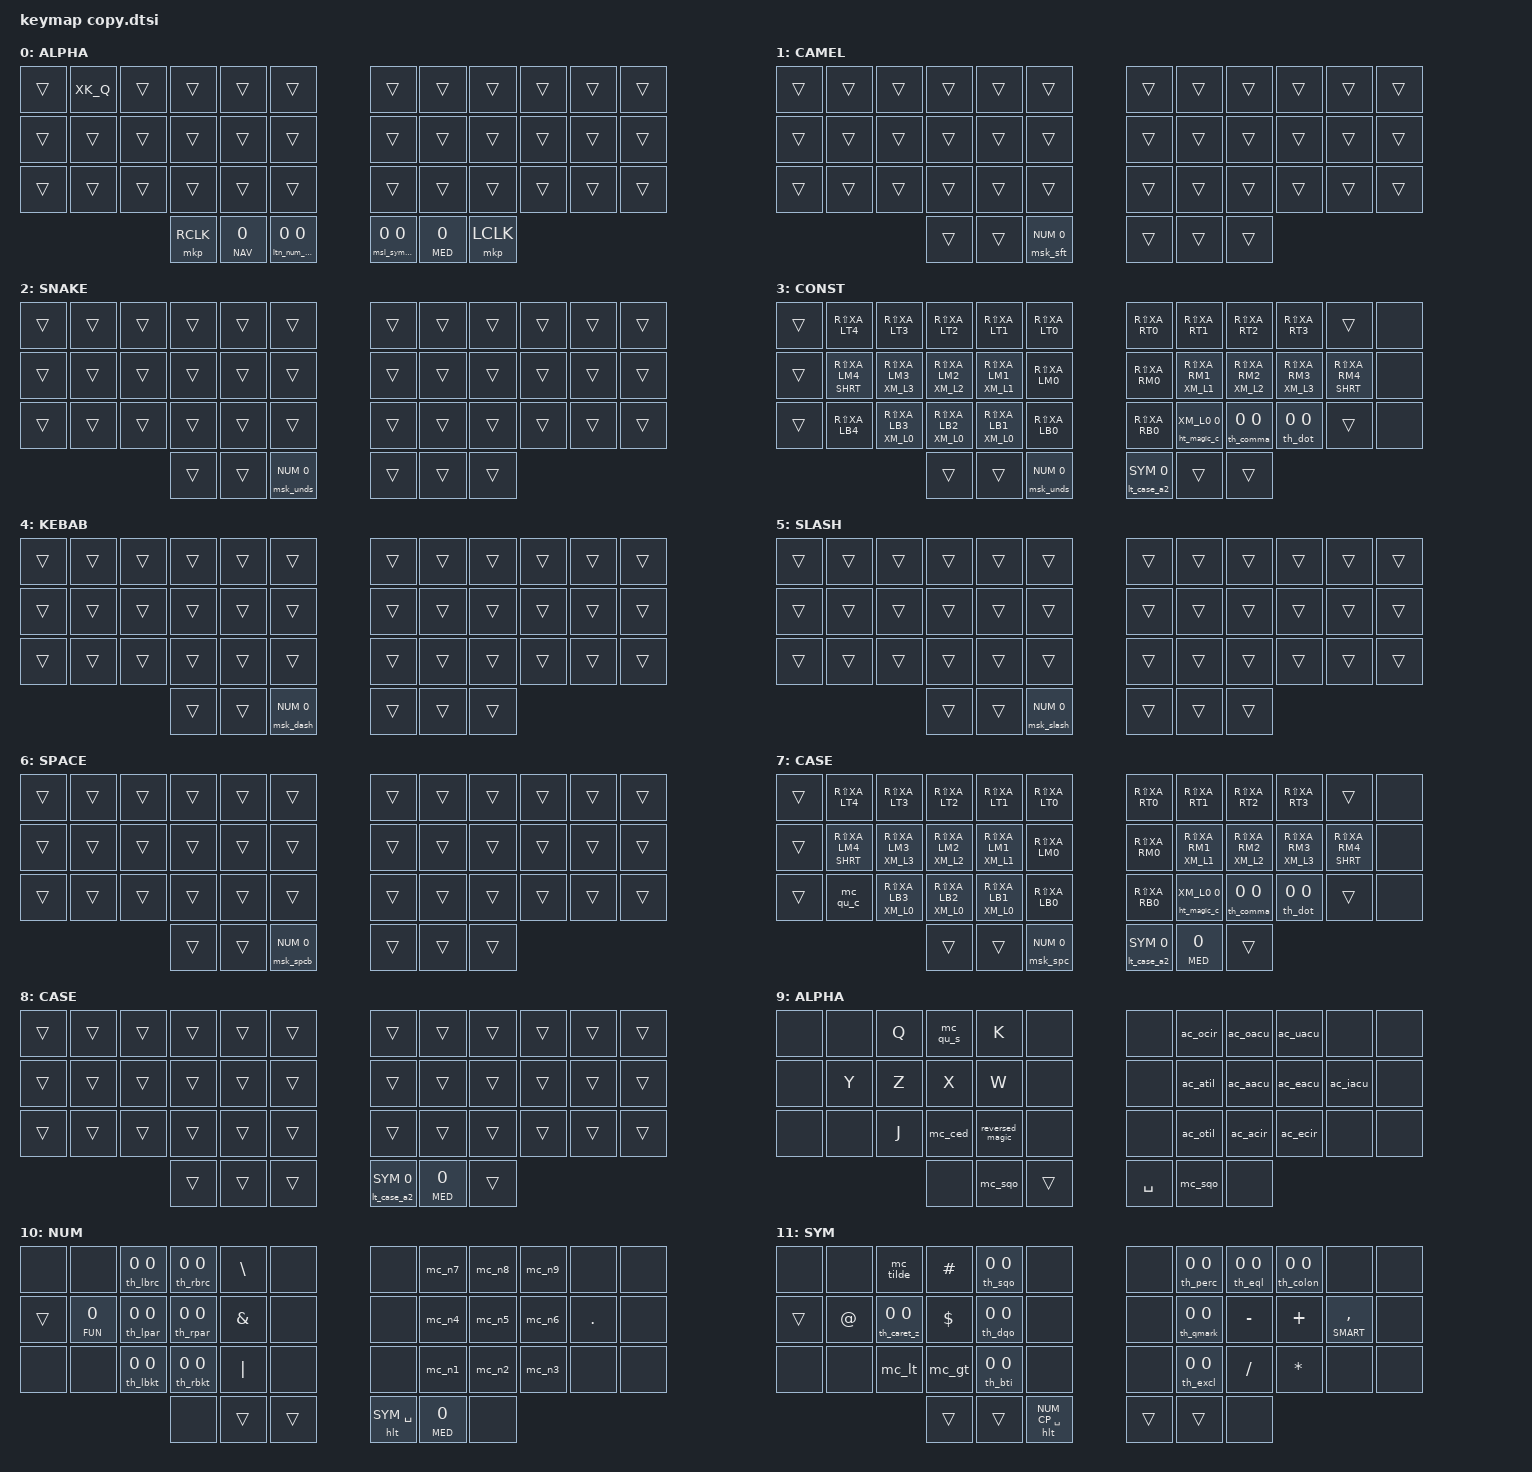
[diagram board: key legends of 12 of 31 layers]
/*
*
* Copyright (c) 2025 Ryan Luckie
* SPDX-License-Identifier: MIT
*
*/
/ {
      keymap {
          compatible = "zmk,keymap";
          default {
               display-name = "ALPHA";
               bindings = <
//╭────────────────────┬────────────────────┬────────────────────┬────────────────────┬────────────────────┬────────────────────┬────────────────────┬────────────────────┬────────────────────┬────────────────────┬────────────────────┬────────────────────╮
   // &trans               &kp XK_Q             &kp XK_W             &hrlm LHYP XK_E       &kp XK_R             &kp XK_T             &kp XK_Y            &kp XK_U             &hrrm RHYP XK_I      &kp XK_O             &kp XK_P             &trans
   &trans               &kp XK_Q               &trans               &trans               &trans               &trans               &trans               &trans               &trans               &trans               &trans               &trans
//├────────────────────┼────────────────────┼────────────────────┼────────────────────┼────────────────────┼────────────────────┼────────────────────┼────────────────────┼────────────────────┼────────────────────┼────────────────────┼────────────────────┤
   // &trans               &lt SHRT XK_A        &hrlm LCTRL XK_S     &hrlm LALT XK_D      &hrls LSHFT XK_F     &kp XK_G             &kp XK_H             &hrrs RSHFT XK_J     &hrrm RALT XK_K      &hrrm RCTL XK_L      &lt SHRT XK_SEMI     &trans
   &trans               &trans               &trans               &trans               &trans               &trans               &trans               &trans               &trans               &trans               &trans               &trans
//├────────────────────┼────────────────────┼────────────────────┼────────────────────┼────────────────────┼────────────────────┼────────────────────┼────────────────────┼────────────────────┼────────────────────┼────────────────────┼────────────────────┤
   &trans               &trans               &trans               &trans               &trans               &trans               &trans               &trans               &trans               &trans               &trans               &trans
//╰────────────────────┴────────────────────┴────────────────────┼────────────────────┼────────────────────┼────────────────────┼────────────────────┼────────────────────┼────────────────────┼────────────────────┴────────────────────┴────────────────────╯
                                                                  &mkp RCLK            &ht_repeat NAV 0     &ltn_num_spc 0 0     &msl_sym_a2 0 0      &ht_shift MED 0      &mkp LCLK
//                                                               ╰────────────────────┴────────────────────┴────────────────────┴────────────────────┴────────────────────┴────────────────────╯
                        >;
                };
          camel_case {
               display-name = "CAMEL";
               bindings = <
//╭────────────────────┬────────────────────┬────────────────────┬────────────────────┬────────────────────┬────────────────────┬────────────────────┬────────────────────┬────────────────────┬────────────────────┬────────────────────┬────────────────────╮
   &trans               &trans               &trans               &trans               &trans               &trans               &trans               &trans               &trans               &trans               &trans               &trans
//├────────────────────┼────────────────────┼────────────────────┼────────────────────┼────────────────────┼────────────────────┼────────────────────┼────────────────────┼────────────────────┼────────────────────┼────────────────────┼────────────────────┤
   &trans               &trans               &trans               &trans               &trans               &trans               &trans               &trans               &trans               &trans               &trans               &trans
//├────────────────────┼────────────────────┼────────────────────┼────────────────────┼────────────────────┼────────────────────┼────────────────────┼────────────────────┼────────────────────┼────────────────────┼────────────────────┼────────────────────┤
   &trans               &trans               &trans               &trans               &trans               &trans               &trans               &trans               &trans               &trans               &trans               &trans
//╰────────────────────┴────────────────────┴────────────────────┼────────────────────┼────────────────────┼────────────────────┼────────────────────┼────────────────────┼────────────────────┼────────────────────┴────────────────────┴────────────────────╯
                                                                  &trans               &trans               &msk_sft NUM 0       &trans               &trans               &trans
//                                                               ╰────────────────────┴────────────────────┴────────────────────┴────────────────────┴────────────────────┴────────────────────╯
>;
          };
          snake_case {
               display-name = "SNAKE";
               bindings = <
//╭────────────────────┬────────────────────┬────────────────────┬────────────────────┬────────────────────┬────────────────────┬────────────────────┬────────────────────┬────────────────────┬────────────────────┬────────────────────┬────────────────────╮
   &trans               &trans               &trans               &trans               &trans               &trans               &trans               &trans               &trans               &trans               &trans               &trans
//├────────────────────┼────────────────────┼────────────────────┼────────────────────┼────────────────────┼────────────────────┼────────────────────┼────────────────────┼────────────────────┼────────────────────┼────────────────────┼────────────────────┤
   &trans               &trans               &trans               &trans               &trans               &trans               &trans               &trans               &trans               &trans               &trans               &trans
//├────────────────────┼────────────────────┼────────────────────┼────────────────────┼────────────────────┼────────────────────┼────────────────────┼────────────────────┼────────────────────┼────────────────────┼────────────────────┼────────────────────┤
   &trans               &trans               &trans               &trans               &trans               &trans               &trans               &trans               &trans               &trans               &trans               &trans
//╰────────────────────┴────────────────────┴────────────────────┼────────────────────┼────────────────────┼────────────────────┼────────────────────┼────────────────────┼────────────────────┼────────────────────┴────────────────────┴────────────────────╯
                                                                  &trans               &trans               &msk_unds NUM 0      &trans               &trans               &trans
//                                                               ╰────────────────────┴────────────────────┴────────────────────┴────────────────────┴────────────────────┴────────────────────╯
>;
          };
          constant {
               display-name = "CONST";
               bindings = <
//╭────────────────────┬────────────────────┬────────────────────┬────────────────────┬────────────────────┬────────────────────┬────────────────────┬────────────────────┬────────────────────┬────────────────────┬────────────────────┬────────────────────╮
   &trans               &kp RS(XA_LT4)   &kp RS(XA_LT3)       &kp RS(XA_LT2)   &kp RS(XA_LT1)       &kp RS(XA_LT0)   &kp RS(XA_RT0)       &kp RS(XA_RT1)   &kp RS(XA_RT2)       &kp RS(XA_RT3)         &trans               &none
//├────────────────────┼────────────────────┼────────────────────┼────────────────────┼────────────────────┼────────────────────┼────────────────────┼────────────────────┼────────────────────┼────────────────────┼────────────────────┼────────────────────┤
   &trans               &lt SHRT RS(XA_LM4)    &mt XM_L3 RS(XA_LM3)   &mt XM_L2 RS(XA_LM2)   &mt XM_L1 RS(XA_LM1)   &kp RS(XA_LM0)       &kp RS(XA_RM0)   &mt XM_L1 RS(XA_RM1)   &mt XM_L2 RS(XA_RM2)   &mt XM_L3 RS(XA_RM3)   &lt SHRT RS(XA_RM4)  &none
//├────────────────────┼────────────────────┼────────────────────┼────────────────────┼────────────────────┼────────────────────┼────────────────────┼────────────────────┼────────────────────┼────────────────────┼────────────────────┼────────────────────┤
   &trans               &kp RS(XA_LB4)   &mt XM_L0 RS(XA_LB3)   &mt XM_L0 RS(XA_LB2)   &mt XM_L0 RS(XA_LB1)   &kp RS(XA_LB0)       &kp RS(XA_RB0)   &ht_magic_c XM_L0 0    &th_comma 0 0        &th_dot 0 0            &trans               &none
//╰────────────────────┴────────────────────┴────────────────────┼────────────────────┼────────────────────┼────────────────────┼────────────────────┼────────────────────┼────────────────────┼────────────────────┴────────────────────┴────────────────────╯
                                                                  &trans               &trans               &msk_unds NUM 0      &lt_case_a2 SYM 0    &trans               &trans
//                                                               ╰────────────────────┴────────────────────┴────────────────────┴────────────────────┴────────────────────┴────────────────────╯
>;
          };
          kebab_case {
               display-name = "KEBAB";
               bindings = <
//╭────────────────────┬────────────────────┬────────────────────┬────────────────────┬────────────────────┬────────────────────┬────────────────────┬────────────────────┬────────────────────┬────────────────────┬────────────────────┬────────────────────╮
   &trans               &trans               &trans               &trans               &trans               &trans               &trans               &trans               &trans               &trans               &trans               &trans
//├────────────────────┼────────────────────┼────────────────────┼────────────────────┼────────────────────┼────────────────────┼────────────────────┼────────────────────┼────────────────────┼────────────────────┼────────────────────┼────────────────────┤
   &trans               &trans               &trans               &trans               &trans               &trans               &trans               &trans               &trans               &trans               &trans               &trans
//├────────────────────┼────────────────────┼────────────────────┼────────────────────┼────────────────────┼────────────────────┼────────────────────┼────────────────────┼────────────────────┼────────────────────┼────────────────────┼────────────────────┤
   &trans               &trans               &trans               &trans               &trans               &trans               &trans               &trans               &trans               &trans               &trans               &trans
//╰────────────────────┴────────────────────┴────────────────────┼────────────────────┼────────────────────┼────────────────────┼────────────────────┼────────────────────┼────────────────────┼────────────────────┴────────────────────┴────────────────────╯
                                                                  &trans               &trans               &msk_dash NUM 0      &trans               &trans               &trans
//                                                               ╰────────────────────┴────────────────────┴────────────────────┴────────────────────┴────────────────────┴────────────────────╯
>;
          };
          slash_case {
               display-name = "SLASH";
               bindings = <
//╭────────────────────┬────────────────────┬────────────────────┬────────────────────┬────────────────────┬────────────────────┬────────────────────┬────────────────────┬────────────────────┬────────────────────┬────────────────────┬────────────────────╮
   &trans               &trans               &trans               &trans               &trans               &trans               &trans               &trans               &trans               &trans               &trans               &trans
//├────────────────────┼────────────────────┼────────────────────┼────────────────────┼────────────────────┼────────────────────┼────────────────────┼────────────────────┼────────────────────┼────────────────────┼────────────────────┼────────────────────┤
   &trans               &trans               &trans               &trans               &trans               &trans               &trans               &trans               &trans               &trans               &trans               &trans
//├────────────────────┼────────────────────┼────────────────────┼────────────────────┼────────────────────┼────────────────────┼────────────────────┼────────────────────┼────────────────────┼────────────────────┼────────────────────┼────────────────────┤
   &trans               &trans               &trans               &trans               &trans               &trans               &trans               &trans               &trans               &trans               &trans               &trans
//╰────────────────────┴────────────────────┴────────────────────┼────────────────────┼────────────────────┼────────────────────┼────────────────────┼────────────────────┼────────────────────┼────────────────────┴────────────────────┴────────────────────╯
                                                                  &trans               &trans               &msk_slash NUM 0     &trans               &trans               &trans
//                                                               ╰────────────────────┴────────────────────┴────────────────────┴────────────────────┴────────────────────┴────────────────────╯
>;
          };
          spacing {
               display-name = "SPACE";
               bindings = <
//╭────────────────────┬────────────────────┬────────────────────┬────────────────────┬────────────────────┬────────────────────┬────────────────────┬────────────────────┬────────────────────┬────────────────────┬────────────────────┬────────────────────╮
   &trans               &trans               &trans               &trans               &trans               &trans               &trans               &trans               &trans               &trans               &trans               &trans
//├────────────────────┼────────────────────┼────────────────────┼────────────────────┼────────────────────┼────────────────────┼────────────────────┼────────────────────┼────────────────────┼────────────────────┼────────────────────┼────────────────────┤
   &trans               &trans               &trans               &trans               &trans               &trans               &trans               &trans               &trans               &trans               &trans               &trans
//├────────────────────┼────────────────────┼────────────────────┼────────────────────┼────────────────────┼────────────────────┼────────────────────┼────────────────────┼────────────────────┼────────────────────┼────────────────────┼────────────────────┤
   &trans               &trans               &trans               &trans               &trans               &trans               &trans               &trans               &trans               &trans               &trans               &trans
//╰────────────────────┴────────────────────┴────────────────────┼────────────────────┼────────────────────┼────────────────────┼────────────────────┼────────────────────┼────────────────────┼────────────────────┴────────────────────┴────────────────────╯
                                                                  &trans               &trans               &msk_spcb NUM 0      &trans               &trans               &trans
//                                                               ╰────────────────────┴────────────────────┴────────────────────┴────────────────────┴────────────────────┴────────────────────╯
>;
          };
          capsword {
               display-name = "CASE";
               bindings = <
//╭────────────────────┬────────────────────┬────────────────────┬────────────────────┬────────────────────┬────────────────────┬────────────────────┬────────────────────┬────────────────────┬────────────────────┬────────────────────┬────────────────────╮
   &trans               &kp RS(XA_LT4)       &kp RS(XA_LT3)       &kp RS(XA_LT2)       &kp RS(XA_LT1)       &kp RS(XA_LT0)       &kp RS(XA_RT0)       &kp RS(XA_RT1)       &kp RS(XA_RT2)       &kp RS(XA_RT3)       &trans               &none
//├────────────────────┼────────────────────┼────────────────────┼────────────────────┼────────────────────┼────────────────────┼────────────────────┼────────────────────┼────────────────────┼────────────────────┼────────────────────┼────────────────────┤
   &trans               &lt SHRT RS(XA_LM4)  &mt XM_L3 RS(XA_LM3) &mt XM_L2 RS(XA_LM2) &mt XM_L1 RS(XA_LM1) &kp RS(XA_LM0)       &kp RS(XA_RM0)       &mt XM_L1 RS(XA_RM1) &mt XM_L2 RS(XA_RM2) &mt XM_L3 RS(XA_RM3) &lt SHRT RS(XA_RM4)  &none
//├────────────────────┼────────────────────┼────────────────────┼────────────────────┼────────────────────┼────────────────────┼────────────────────┼────────────────────┼────────────────────┼────────────────────┼────────────────────┼────────────────────┤
   &trans               &mc_qu_c             &mt XM_L0 RS(XA_LB3) &mt XM_L0 RS(XA_LB2) &mt XM_L0 RS(XA_LB1) &kp RS(XA_LB0)       &kp RS(XA_RB0)       &ht_magic_c XM_L0 0  &th_comma 0 0        &th_dot 0 0          &trans               &none
//╰────────────────────┴────────────────────┴────────────────────┼────────────────────┼────────────────────┼────────────────────┼────────────────────┼────────────────────┼────────────────────┼────────────────────┴────────────────────┴────────────────────╯
                                                                  &trans               &trans               &msk_spc NUM 0       &lt_case_a2 SYM 0    &lt_cancel MED 0     &trans
//                                                               ╰────────────────────┴────────────────────┴────────────────────┴────────────────────┴────────────────────┴────────────────────╯
>;
          };
          capsline {
               display-name = "CASE";
               bindings = <
//╭────────────────────┬────────────────────┬────────────────────┬────────────────────┬────────────────────┬────────────────────┬────────────────────┬────────────────────┬────────────────────┬────────────────────┬────────────────────┬────────────────────╮
   &trans               &trans               &trans               &trans               &trans               &trans               &trans               &trans               &trans               &trans               &trans               &trans
//├────────────────────┼────────────────────┼────────────────────┼────────────────────┼────────────────────┼────────────────────┼────────────────────┼────────────────────┼────────────────────┼────────────────────┼────────────────────┼────────────────────┤
   &trans               &trans               &trans               &trans               &trans               &trans               &trans               &trans               &trans               &trans               &trans               &trans
//├────────────────────┼────────────────────┼────────────────────┼────────────────────┼────────────────────┼────────────────────┼────────────────────┼────────────────────┼────────────────────┼────────────────────┼────────────────────┼────────────────────┤
   &trans               &trans               &trans               &trans               &trans               &trans               &trans               &trans               &trans               &trans               &trans               &trans
//╰────────────────────┴────────────────────┴────────────────────┼────────────────────┼────────────────────┼────────────────────┼────────────────────┼────────────────────┼────────────────────┼────────────────────┴────────────────────┴────────────────────╯
                                                                  &trans               &trans               &trans               &lt_case_a2 SYM 0    &lt_cancel MED 0     &trans
//                                                               ╰────────────────────┴────────────────────┴────────────────────┴────────────────────┴────────────────────┴────────────────────╯
>;
          };
          alpha2 {
               display-name = "ALPHA";
               bindings = <
//╭────────────────────┬────────────────────┬────────────────────┬────────────────────┬────────────────────┬────────────────────┬────────────────────┬────────────────────┬────────────────────┬────────────────────┬────────────────────┬────────────────────╮
   &none                &none                &kp Q                &mc_qu_s             &kp K                &none                &none                &ac_ocir             &ac_oacu             &ac_uacu             &none                &none
//├────────────────────┼────────────────────┼────────────────────┼────────────────────┼────────────────────┼────────────────────┼────────────────────┼────────────────────┼────────────────────┼────────────────────┼────────────────────┼────────────────────┤
   &none                &kp Y                &kp Z                &kp X                &kp W                &none                &none                &ac_atil             &ac_aacu             &ac_eacu             &ac_iacu             &none
//├────────────────────┼────────────────────┼────────────────────┼────────────────────┼────────────────────┼────────────────────┼────────────────────┼────────────────────┼────────────────────┼────────────────────┼────────────────────┼────────────────────┤
   &none                &none                &kp J                &mc_ced              &reversed_magic      &none                &none                &ac_otil             &ac_acir             &ac_ecir             &none                &none
//╰────────────────────┴────────────────────┴────────────────────┼────────────────────┼────────────────────┼────────────────────┼────────────────────┼────────────────────┼────────────────────┼────────────────────┴────────────────────┴────────────────────╯
                                                                  &none                &mc_sqo              &trans               &kp SPACE            &mc_sqo              &none
//                                                               ╰────────────────────┴────────────────────┴────────────────────┴────────────────────┴────────────────────┴────────────────────╯
>;
          };

          numbers {
               display-name = "NUM";
               bindings = <
//╭────────────────────┬────────────────────┬────────────────────┬────────────────────┬────────────────────┬────────────────────┬────────────────────┬────────────────────┬────────────────────┬────────────────────┬────────────────────┬────────────────────╮
   &none                &none                &th_lbrc 0 0         &th_rbrc 0 0         &kp BSLH             &none                &none                &mc_n7               &mc_n8               &mc_n9               &none                &none
//├────────────────────┼────────────────────┼────────────────────┼────────────────────┼────────────────────┼────────────────────┼────────────────────┼────────────────────┼────────────────────┼────────────────────┼────────────────────┼────────────────────┤
   &trans               &lt_deg FUN 0        &th_lpar 0 0         &th_rpar 0 0         &kp AMPS             &none                &none                &mc_n4               &mc_n5               &mc_n6               &kp DOT              &none
//├────────────────────┼────────────────────┼────────────────────┼────────────────────┼────────────────────┼────────────────────┼────────────────────┼────────────────────┼────────────────────┼────────────────────┼────────────────────┼────────────────────┤
   &none                &none                &th_lbkt 0 0         &th_rbkt 0 0         &kp PIPE             &none                &none                &mc_n1               &mc_n2               &mc_n3               &none                &none
//╰────────────────────┴────────────────────┴────────────────────┼────────────────────┼────────────────────┼────────────────────┼────────────────────┼────────────────────┼────────────────────┼────────────────────┴────────────────────┴────────────────────╯
                                                                 &none                 &trans               &trans               &hlt SYM SPACE       &lt_n0 MED 0       &none
//                                                               ╰────────────────────┴────────────────────┴────────────────────┴────────────────────┴────────────────────┴────────────────────╯
>;
          };
          symbols {
               display-name = "SYM";
               bindings = <
//╭────────────────────┬────────────────────┬────────────────────┬────────────────────┬────────────────────┬────────────────────┬────────────────────┬────────────────────┬────────────────────┬────────────────────┬────────────────────┬────────────────────╮
   &none                &none                &mc_tilde            &kp HASH             &th_sqo 0 0          &none                &none                &th_perc 0 0         &th_eql 0 0          &th_colon 0 0        &none                &none
//├────────────────────┼────────────────────┼────────────────────┼────────────────────┼────────────────────┼────────────────────┼────────────────────┼────────────────────┼────────────────────┼────────────────────┼────────────────────┼────────────────────┤
   &trans               &kp AT               &th_caret_z 0 0      &kp DOLLAR           &th_dqo 0 0          &none                &none                &th_qmark 0 0        &kp MINUS            &kp PLUS             &lt SMART COMMA      &none
//├────────────────────┼────────────────────┼────────────────────┼────────────────────┼────────────────────┼────────────────────┼────────────────────┼────────────────────┼────────────────────┼────────────────────┼────────────────────┼────────────────────┤
   &none                &none                &mc_lt               &mc_gt               &th_bti 0 0          &none                &none                &th_excl 0 0         &kp SLASH            &kp STAR             &none                &none
//╰────────────────────┴────────────────────┴────────────────────┼────────────────────┼────────────────────┼────────────────────┼────────────────────┼────────────────────┼────────────────────┼────────────────────┴────────────────────┴────────────────────╯
                                                                  &trans               &trans               &hlt NUM_CP SPACE    &trans               &trans               &none
//                                                               ╰────────────────────┴────────────────────┴────────────────────┴────────────────────┴────────────────────┴────────────────────╯
>;
          };

               sentence_case {
               display-name = "CASE";
               bindings = <
//╭────────────────────┬────────────────────┬────────────────────┬────────────────────┬────────────────────┬────────────────────┬────────────────────┬────────────────────┬────────────────────┬────────────────────┬────────────────────┬────────────────────╮
   &trans               &kp LS(XA_LT4)       &kp LS(XA_LT3)       &kp LS(XA_LT2)       &kp LS(XA_LT1)       &kp LS(XA_LT0)       &kp LS(XA_RT0)       &kp LS(XA_RT1)       &kp LS(XA_RT2)       &kp LS(XA_RT3)       &trans               &none
//├────────────────────┼────────────────────┼────────────────────┼────────────────────┼────────────────────┼────────────────────┼────────────────────┼────────────────────┼────────────────────┼────────────────────┼────────────────────┼────────────────────┤
   &trans               &kp LS(XA_LM4)       &mt XM_L3 LS(XA_LM3) &mt XM_L2 LS(XA_LM2) &mt XM_L1 LS(XA_LM1) &kp LS(XA_LM0)       &kp LS(XA_RM0)       &mt XM_L1 LS(XA_RM1) &mt XM_L2 LS(XA_RM2) &mt XM_L3 LS(XA_RM3) &kp LS(XA_RM4)       &none
//├────────────────────┼────────────────────┼────────────────────┼────────────────────┼────────────────────┼────────────────────┼────────────────────┼────────────────────┼────────────────────┼────────────────────┼────────────────────┼────────────────────┤
   &trans               &kp LS(XA_LB4)       &mt XM_L0 LS(XA_LB3) &mt XM_L0 LS(XA_LB2) &mt XM_L0 LS(XA_LB1) &kp LS(XA_LB0)       &kp LS(XA_RB0)       &ht_magic_c XM_L0 0  &th_comma 0 0        &th_dot 0 0          &trans               &none
//╰────────────────────┴────────────────────┴────────────────────┼────────────────────┼────────────────────┼────────────────────┼────────────────────┼────────────────────┼────────────────────┼────────────────────┴────────────────────┴────────────────────╯
                                                                  &trans               &trans               &trans               &lt_sft_a2 SYM_CP 0  &trans               &none
//                                                               ╰────────────────────┴────────────────────┴────────────────────┴────────────────────┴────────────────────┴────────────────────╯
>;
          };
          ccedil {
               display-name = "Ç EXT";
               bindings = <
//╭────────────────────┬────────────────────┬────────────────────┬────────────────────┬────────────────────┬────────────────────┬────────────────────┬────────────────────┬────────────────────┬────────────────────┬────────────────────┬────────────────────╮
   &none                &none                &none                &none                &none                &none                &none                &none                &trans               &trans               &none                &none
//├────────────────────┼────────────────────┼────────────────────┼────────────────────┼────────────────────┼────────────────────┼────────────────────┼────────────────────┼────────────────────┼────────────────────┼────────────────────┼────────────────────┤
   &none                &none                &none                &none                &mc_aotil            &trans               &trans               &ac_atil             &trans               &none                &none                &none
//├────────────────────┼────────────────────┼────────────────────┼────────────────────┼────────────────────┼────────────────────┼────────────────────┼────────────────────┼────────────────────┼────────────────────┼────────────────────┼────────────────────┤
   &none                &none                &none                &none                &mc_otiles           &trans               &trans               &ac_otil             &trans               &trans               &none                &none
//╰────────────────────┴────────────────────┴────────────────────┼────────────────────┼────────────────────┼────────────────────┼────────────────────┼────────────────────┼────────────────────┼────────────────────┴────────────────────┴────────────────────╯
                                                                  &trans               &sl ALPHA2           &trans               &trans               &trans               &none
//                                                               ╰────────────────────┴────────────────────┴────────────────────┴────────────────────┴────────────────────┴────────────────────╯
>;
          };
          shifted_alpha2 {
               display-name = "ALPHA";
               bindings = <
//╭────────────────────┬────────────────────┬────────────────────┬────────────────────┬────────────────────┬────────────────────┬────────────────────┬────────────────────┬────────────────────┬────────────────────┬────────────────────┬────────────────────╮
   &none                &none                &kp LS(XA_LT4)       &mc_qu_s             &kp LS(XA_LT0)       &trans               &trans               &ac_ocir_s           &ac_oacu_s           &ac_uacu_s           &none                &none
//├────────────────────┼────────────────────┼────────────────────┼────────────────────┼────────────────────┼────────────────────┼────────────────────┼────────────────────┼────────────────────┼────────────────────┼────────────────────┼────────────────────┤
   &trans               &kp LS(XA_LB4)       &kp LS(XA_RM0)       &kp LS(XA_RT0)       &kp LS(XA_LM0)       &trans               &trans               &ac_atil_s           &ac_aacu_s           &ac_eacu_s           &ac_iacu_s           &none
//├────────────────────┼────────────────────┼────────────────────┼────────────────────┼────────────────────┼────────────────────┼────────────────────┼────────────────────┼────────────────────┼────────────────────┼────────────────────┼────────────────────┤
   &none                &none                &kp LS(XA_RB0)       &mc_ced_s            &reversed_magic_c    &trans               &trans               &ac_otil_s           &ac_acir_s           &ac_ecir_s           &none                &none
//╰────────────────────┴────────────────────┴────────────────────┼────────────────────┼────────────────────┼────────────────────┼────────────────────┼────────────────────┼────────────────────┼────────────────────┴────────────────────┴────────────────────╯
                                                                  &trans               &mc_sqo              &trans               &kp SPACE            &mc_sqo              &none
//                                                               ╰────────────────────┴────────────────────┴────────────────────┴────────────────────┴────────────────────┴────────────────────╯
>;
          };
          case_alpha2 {
               display-name = "CASE";
               bindings = <
//╭────────────────────┬────────────────────┬────────────────────┬────────────────────┬────────────────────┬────────────────────┬────────────────────┬────────────────────┬────────────────────┬────────────────────┬────────────────────┬────────────────────╮
   &none                &none                &kp RS(XA_LT4)       &mc_qu_c             &kp RS(XA_LT0)       &trans               &trans               &ac_ocir_c           &ac_oacu_c           &ac_uacu_c           &none                &none
//├────────────────────┼────────────────────┼────────────────────┼────────────────────┼────────────────────┼────────────────────┼────────────────────┼────────────────────┼────────────────────┼────────────────────┼────────────────────┼────────────────────┤
   &trans               &kp RS(XA_LB4)        &kp RS(XA_RM0)      &kp RS(XA_RT0)       &kp RS(XA_LM0)       &trans               &trans               &ac_atil_c           &ac_aacu_c           &ac_eacu_c           &ac_iacu_c           &none
//├────────────────────┼────────────────────┼────────────────────┼────────────────────┼────────────────────┼────────────────────┼────────────────────┼────────────────────┼────────────────────┼────────────────────┼────────────────────┼────────────────────┤
   &none                &none                &kp RS(XA_RB0)       &mc_ced_c            &reversed_magic_c    &trans               &trans               &ac_otil_c           &ac_acir_c           &ac_ecir_c           &none                &none
//╰────────────────────┴────────────────────┴────────────────────┼────────────────────┼────────────────────┼────────────────────┼────────────────────┼────────────────────┼────────────────────┼────────────────────┴────────────────────┴────────────────────╯
                                                                  &trans               &mc_sqo             &trans               &kp SPACE            &mc_sqo              &none
//                                                               ╰────────────────────┴────────────────────┴────────────────────┴────────────────────┴────────────────────┴────────────────────╯
>;
          };
          case_ccedil {
               display-name = "CASE";
               bindings = <
//╭────────────────────┬────────────────────┬────────────────────┬────────────────────┬────────────────────┬────────────────────┬────────────────────┬────────────────────┬────────────────────┬────────────────────┬────────────────────┬────────────────────╮
   &none                &none                &none                &none                &none                &none                &none                &none                &trans               &trans               &none                &none
//├────────────────────┼────────────────────┼────────────────────┼────────────────────┼────────────────────┼────────────────────┼────────────────────┼────────────────────┼────────────────────┼────────────────────┼────────────────────┼────────────────────┤
   &none                &none                &none                &none                &mc_aotil_c          &none                &none                &ac_atil_c           &trans               &none                &none                &none
//├────────────────────┼────────────────────┼────────────────────┼────────────────────┼────────────────────┼────────────────────┼────────────────────┼────────────────────┼────────────────────┼────────────────────┼────────────────────┼────────────────────┤
   &none                &none                &none                &none                &mc_otiles_c         &none                &none                &ac_otil_c           &trans               &trans               &none                &none
//╰────────────────────┴────────────────────┴────────────────────┼────────────────────┼────────────────────┼────────────────────┼────────────────────┼────────────────────┼────────────────────┼────────────────────┴────────────────────┴────────────────────╯
                                                                  &trans               &sl CASE_A2          &trans               &trans               &trans               &none
//                                                               ╰────────────────────┴────────────────────┴────────────────────┴────────────────────┴────────────────────┴────────────────────╯
>;
          };

          shortcuts {
               display-name = "SHRT";
               bindings = <
//╭────────────────────┬────────────────────┬────────────────────┬────────────────────┬────────────────────┬────────────────────┬────────────────────┬────────────────────┬────────────────────┬────────────────────┬────────────────────┬────────────────────╮
   &none                &none                &mc_emoji            &mc_files            &mc_screenshot       &none                &none                &mc_lock             &to NUM              &to PLAIN1           &none                &none
//├────────────────────┼────────────────────┼────────────────────┼────────────────────┼────────────────────┼────────────────────┼────────────────────┼────────────────────┼────────────────────┼────────────────────┼────────────────────┼────────────────────┤
   &none                &none                &mc_zoom_out         &mc_zoom_in          &mc_reset_zoom       &none                &none                &mc_leader           &to NAV              &to MED              &none                &none
//├────────────────────┼────────────────────┼────────────────────┼────────────────────┼────────────────────┼────────────────────┼────────────────────┼────────────────────┼────────────────────┼────────────────────┼────────────────────┼────────────────────┤
   &none                &none                &mc_close            &mc_refresh          &mc_reopen           &none                &none                &kp C_SLEEP          &to FUN              &to MEHS             &none                &none
//╰────────────────────┴────────────────────┴────────────────────┼────────────────────┼────────────────────┼────────────────────┼────────────────────┼────────────────────┼────────────────────┼────────────────────┴────────────────────┴────────────────────╯
                                                                  &trans               &ht_repeat TEXT 0    &lt FUN SPACE        &lt SMART SPACE      &ht_repeat TEXT 0    &none
//                                                               ╰────────────────────┴────────────────────┴────────────────────┴────────────────────┴────────────────────┴────────────────────╯
>;
          };
          mehs {
               display-name = "MEHS";
               bindings = <
//╭────────────────────┬────────────────────┬────────────────────┬────────────────────┬────────────────────┬────────────────────┬────────────────────┬────────────────────┬────────────────────┬────────────────────┬────────────────────┬────────────────────╮
   &none                &none                &mc_meh_b            &mc_meh_m            &mc_meh_g            &none                &none                &mc_meh_l            &mc_meh_o            &mc_meh_u            &none                &none
//├────────────────────┼────────────────────┼────────────────────┼────────────────────┼────────────────────┼────────────────────┼────────────────────┼────────────────────┼────────────────────┼────────────────────┼────────────────────┼────────────────────┤
   &trans               &mc_meh_d            &mc_meh_n            &mc_meh_s            &mc_meh_t            &none                &none                &mc_meh_r            &mc_meh_a            &mc_meh_e            &mc_meh_i            &none
//├────────────────────┼────────────────────┼────────────────────┼────────────────────┼────────────────────┼────────────────────┼────────────────────┼────────────────────┼────────────────────┼────────────────────┼────────────────────┼────────────────────┤
   &none                &none                &mt_meh_f XM_L0 0    &mt_meh_c XM_L0 0    &mt_meh_p XM_L0 0    &none                &none                &mt_meh_h XM_L0 0    &mt_meh_comm XM_L0 0 &mt_meh_dot XM_L0 0  &none                &none
//╰────────────────────┴────────────────────┴────────────────────┼────────────────────┼────────────────────┼────────────────────┼────────────────────┼────────────────────┼────────────────────┼────────────────────┴────────────────────┴────────────────────╯
                                                                  &trans               &lt_plain1 NAV 0     &hsk XM_L0 XM_L0     &hsk XM_L0 XM_L0     &lt_plain1 NAV 0     &none
//                                                               ╰────────────────────┴────────────────────┴────────────────────┴────────────────────┴────────────────────┴────────────────────╯
>;
          };

          plain1 {
               display-name = "PLAIN";
               bindings = <
//╭────────────────────┬────────────────────┬────────────────────┬────────────────────┬────────────────────┬────────────────────┬────────────────────┬────────────────────┬────────────────────┬────────────────────┬────────────────────┬────────────────────╮
   &trans               &kp Q                &kp B                &kp M                &kp G                &kp K                &kp X                &kp L                &kp O                &kp U                &trans               &none
//├────────────────────┼────────────────────┼────────────────────┼────────────────────┼────────────────────┼────────────────────┼────────────────────┼────────────────────┼────────────────────┼────────────────────┼────────────────────┼────────────────────┤
   &trans               &kp D                &kp N                &kp S                &kp T                &kp W                &kp Z                &kp R                &kp A                &kp E                &kp I               &none
//├────────────────────┼────────────────────┼────────────────────┼────────────────────┼────────────────────┼────────────────────┼────────────────────┼────────────────────┼────────────────────┼────────────────────┼────────────────────┼────────────────────┤
   &trans               &kp Y                &kp F                &kp C                &kp P                &kp V                &kp J                &kp H                &kp COMMA            &kp DOT              &trans               &none
//╰────────────────────┴────────────────────┴────────────────────┼────────────────────┼────────────────────┼────────────────────┼────────────────────┼────────────────────┼────────────────────┼────────────────────┴────────────────────┴────────────────────╯
                                                                  &trans               &ht_repeat NAV 0     &lt NUM_CP SPACE     &msl_p2 SYM_CP 0     &ht_sft_p2 MED       &none
//                                                               ╰────────────────────┴────────────────────┴────────────────────┴────────────────────┴────────────────────┴────────────────────╯
>;
          };
          plain2 {
               display-name = "PLAIN";
               bindings = <

   &none                &none                &kp Q                &mc_qu               &kp K                &none                &none                &ac_ocir            &ac_oacu             &ac_uacu            &none                &none
//├────────────────────┼────────────────────┼────────────────────┼────────────────────┼────────────────────┼────────────────────┼────────────────────┼────────────────────┼────────────────────┼────────────────────┼────────────────────┼────────────────────┤
   &trans               &kp Y            &kp Z                &kp X            &kp W                &none                &none                &ac_atil            &ac_aacu             &ac_eacu            &ac_iacu             &none
//├────────────────────┼────────────────────┼────────────────────┼────────────────────┼────────────────────┼────────────────────┼────────────────────┼────────────────────┼────────────────────┼────────────────────┼────────────────────┼────────────────────┤
   &none                &none                &kp J                &mc_ced             &kp V                &none                &none                &ac_otil            &ac_acir             &ac_ecir            &none                &none
//╰────────────────────┴────────────────────┴────────────────────┼────────────────────┼────────────────────┼────────────────────┼────────────────────┼────────────────────┼────────────────────┼────────────────────┴────────────────────┴────────────────────╯
                                                                  &trans               &mc_sqo             &lt NUM_CP SPACE     &lt SYM_CP SPACE   &mc_sqo              &none
//                                                               ╰────────────────────┴────────────────────┴────────────────────┴────────────────────┴────────────────────┴────────────────────╯
>;
          };
          shifted_plain2 {
               display-name = "PLAIN";
               bindings = <
//╭────────────────────┬────────────────────┬────────────────────┬────────────────────┬────────────────────┬────────────────────┬────────────────────┬────────────────────┬────────────────────┬────────────────────┬────────────────────┬────────────────────╮
   &none                &none                &kp LS(XA_LT4)       &mc_qu_s            &kp LS(XA_LT0)       &none                &none                &ac_ocir_s           &ac_oacu_s   &ac_uacu_s           &none                &none
//├────────────────────┼────────────────────┼────────────────────┼────────────────────┼────────────────────┼────────────────────┼────────────────────┼────────────────────┼────────────────────┼────────────────────┼────────────────────┼────────────────────┤
   &trans               &kp LS(XA_LB4)       &kp LS(XA_RM0)       &kp LS(XA_RT0)   &kp LS(XA_LM0)       &none                &none                &ac_atil_s           &ac_aacu_s   &ac_eacu_s           &ac_iacu_s  &none
//├────────────────────┼────────────────────┼────────────────────┼────────────────────┼────────────────────┼────────────────────┼────────────────────┼────────────────────┼────────────────────┼────────────────────┼────────────────────┼────────────────────┤
   &none                &none                &kp LS(XA_RB0)       &mc_ced_s            &kp LS(XA_LB0)       &none                &none                &ac_otil_s           &ac_acir_s   &ac_ecir_s           &none                &none
//╰────────────────────┴────────────────────┴────────────────────┼────────────────────┼────────────────────┼────────────────────┼────────────────────┼────────────────────┼────────────────────┼────────────────────┴────────────────────┴────────────────────╯
                                                                  &trans               &mc_sqo             &lt NUM_CP SPACE     &lt SYM_CP SPACE   &mc_sqo              &none
//                                                               ╰────────────────────┴────────────────────┴────────────────────┴────────────────────┴────────────────────┴────────────────────╯
>;
          };
          secondary_alternate_repeat {
               display-name = "ALPHA";
               bindings = <
//╭────────────────────┬────────────────────┬────────────────────┬────────────────────┬────────────────────┬────────────────────┬────────────────────┬────────────────────┬────────────────────┬────────────────────┬────────────────────┬────────────────────╮
   &trans               &trans               &trans               &trans               &trans               &trans               &trans               &trans               &trans               &trans               &trans               &trans
//├────────────────────┼────────────────────┼────────────────────┼────────────────────┼────────────────────┼────────────────────┼────────────────────┼────────────────────┼────────────────────┼────────────────────┼────────────────────┼────────────────────┤
   &trans               &trans               &trans               &trans               &trans               &trans               &trans               &trans               &trans               &trans               &trans               &trans
//├────────────────────┼────────────────────┼────────────────────┼────────────────────┼────────────────────┼────────────────────┼────────────────────┼────────────────────┼────────────────────┼────────────────────┼────────────────────┼────────────────────┤
   &trans               &trans               &trans               &trans               &trans               &trans               &trans               &trans               &trans               &trans               &trans               &trans
//╰────────────────────┴────────────────────┴────────────────────┼────────────────────┼────────────────────┼────────────────────┼────────────────────┼────────────────────┼────────────────────┼────────────────────┴────────────────────┴────────────────────╯
                                                                  &trans               &a2_alt_repeat       &trans               &trans               &trans               &trans
//                                                               ╰────────────────────┴────────────────────┴────────────────────┴────────────────────┴────────────────────┴────────────────────╯
>;
          };

          navigation {
               display-name = "NAV";
               bindings = <
//╭────────────────────┬────────────────────┬────────────────────┬────────────────────┬────────────────────┬────────────────────┬────────────────────┬────────────────────┬────────────────────┬────────────────────┬────────────────────┬────────────────────╮
   &none                &none                &mc_swapper          &mc_tabs            &mc_launcher         &none                &none                &kp TAB              &kp ENTER            &kp ESC              &none                &none
//├────────────────────┼────────────────────┼────────────────────┼────────────────────┼────────────────────┼────────────────────┼────────────────────┼────────────────────┼────────────────────┼────────────────────┼────────────────────┼────────────────────┤
   &trans               &lt TEXT INS         &kp XM_L3            &kp XM_L2        &kp XM_L1            &none                &none                &kp LEFT          &kp DOWN             &kp UP           &kp RIGHT            &none
//├────────────────────┼────────────────────┼────────────────────┼────────────────────┼────────────────────┼────────────────────┼────────────────────┼────────────────────┼────────────────────┼────────────────────┼────────────────────┼────────────────────┤
   &none                &none                &kp XM_L0            &kp XM_L0        &kp XM_L0            &none                &none                &kp DEL          &kp HOME             &kp END          &none                &none
//╰────────────────────┴────────────────────┴────────────────────┼────────────────────┼────────────────────┼────────────────────┼────────────────────┼────────────────────┼────────────────────┼────────────────────┴────────────────────┴────────────────────╯
                                                                  &trans               &trans               &trans               &hlt SYM_CP SPACE &mo MED              &none
//                                                               ╰────────────────────┴────────────────────┴────────────────────┴────────────────────┴────────────────────┴────────────────────╯
>;
          };
          numbers_copy {
               display-name = "NUM";
               bindings = <
//╭────────────────────┬────────────────────┬────────────────────┬────────────────────┬────────────────────┬────────────────────┬────────────────────┬────────────────────┬────────────────────┬────────────────────┬────────────────────┬────────────────────╮
   &none                &none                &th_lbrc 0 0         &th_rbrc 0 0   &kp BSLH             &none                &none                &mc_n7               &mc_n8   &mc_n9               &none                &none
//├────────────────────┼────────────────────┼────────────────────┼────────────────────┼────────────────────┼────────────────────┼────────────────────┼────────────────────┼────────────────────┼────────────────────┼────────────────────┼────────────────────┤
   &trans               &mc_deg             &th_lpar 0 0   &th_rpar 0 0   &kp AMPS             &none                &none                &mc_n4               &mc_n5   &mc_n6               &kp DOT  &none
//├────────────────────┼────────────────────┼────────────────────┼────────────────────┼────────────────────┼────────────────────┼────────────────────┼────────────────────┼────────────────────┼────────────────────┼────────────────────┼────────────────────┤
   &none                &none                &th_lbkt 0 0   &th_rbkt 0 0   &kp PIPE             &none                &none                &mc_n1               &mc_n2   &mc_n3               &none                &none
//╰────────────────────┴────────────────────┴────────────────────┼────────────────────┼────────────────────┼────────────────────┼────────────────────┼────────────────────┼────────────────────┼────────────────────┴────────────────────┴────────────────────╯
                                                                  &trans               &trans               &trans               &hlt SYM_CP SPACE    &lt_n0 MED 0         &none
//                                                               ╰────────────────────┴────────────────────┴────────────────────┴────────────────────┴────────────────────┴────────────────────╯
>;
          };
          symbols_copy {
               display-name = "SYM";
               bindings = <
//╭────────────────────┬────────────────────┬────────────────────┬────────────────────┬────────────────────┬────────────────────┬────────────────────┬────────────────────┬────────────────────┬────────────────────┬────────────────────┬────────────────────╮
   &none                &none                &mc_tilde            &kp HASH             &th_sqo 0 0          &none                &none                &th_perc 0 0         &th_eql 0 0          &th_colon 0 0        &none                &none
//├────────────────────┼────────────────────┼────────────────────┼────────────────────┼────────────────────┼────────────────────┼────────────────────┼────────────────────┼────────────────────┼────────────────────┼────────────────────┼────────────────────┤
   &trans               &kp AT               &th_caret_z 0 0      &kp DOLLAR           &th_dqo 0 0          &none                &none                &th_qmark 0 0        &kp MINUS            &kp PLUS             &kp STAR             &none
//├────────────────────┼────────────────────┼────────────────────┼────────────────────┼────────────────────┼────────────────────┼────────────────────┼────────────────────┼────────────────────┼────────────────────┼────────────────────┼────────────────────┤
   &none                &none                &mc_lt               &mc_gt               &th_bti 0 0          &none                &none                &th_excl 0 0         &kp SLASH            &kp STAR             &none                &none
//╰────────────────────┴────────────────────┴────────────────────┼────────────────────┼────────────────────┼────────────────────┼────────────────────┼────────────────────┼────────────────────┼────────────────────┴────────────────────┴────────────────────╯
                                                                  &trans               &trans               &kp SPACE            &kp SPACE            &trans               &none
//                                                               ╰────────────────────┴────────────────────┴────────────────────┴────────────────────┴────────────────────┴────────────────────╯
>;
          };
          MED {
                    display-name = "MOUSE";
                    bindings = <
//╭────────────────────┬────────────────────┬────────────────────┬────────────────────┬────────────────────┬────────────────────┬────────────────────┬────────────────────┬────────────────────┬────────────────────┬────────────────────┬────────────────────╮
   &none                &none                &none                &mkp LCLK            &mkp RCLK            &trans               &trans               &mc_hand            &kp ENTER            &kp ESC
//├────────────────────┼────────────────────┼────────────────────┼────────────────────┼────────────────────┼────────────────────┼────────────────────┼────────────────────┼────────────────────┼────────────────────┼────────────────────┼────────────────────┤
   &none                &none                &mmv MOVE_LEFT       &mmv MOVE_UP         &mmv MOVE_RIGHT      &trans               &trans               &mc_mic             &mt C_MUTE C_VOL_DN  &kp C_VOL_UP &lt_cam TEXT 0       &none
//├────────────────────┼────────────────────┼────────────────────┼────────────────────┼────────────────────┼────────────────────┼────────────────────┼────────────────────┼────────────────────┼────────────────────┼────────────────────┼────────────────────┤
   &none                &none                &msc SCRL_DOWN       &mmv MOVE_DOWN       &msc SCRL_UP         &trans               &trans               &kp C_PP             &kp C_PREV           &kp C_NEXT           &none                &none
//╰────────────────────┴────────────────────┴────────────────────┼────────────────────┼────────────────────┼────────────────────┼────────────────────┼────────────────────┼────────────────────┼────────────────────┴────────────────────┴────────────────────╯
                                                                  &none                &mo NAV_CP            &kp SPACE           &none                &trans                &none
//                                                               ╰────────────────────┴────────────────────┴────────────────────┴────────────────────┴────────────────────┴────────────────────╯
>;
          };
          navigation_copy {
               display-name = "NAV";
               bindings = <
//╭────────────────────┬────────────────────┬────────────────────┬────────────────────┬────────────────────┬────────────────────┬────────────────────┬────────────────────┬────────────────────┬────────────────────┬────────────────────┬────────────────────╮
   &none                &none                &mc_swapper          &mc_tabs             &mc_launcher         &none                &none                &kp TAB              &kp ENTER            &kp ESC              &none                &none
//├────────────────────┼────────────────────┼────────────────────┼────────────────────┼────────────────────┼────────────────────┼────────────────────┼────────────────────┼────────────────────┼────────────────────┼────────────────────┼────────────────────┤
   &trans               &kp INS              &kp XM_L3            &kp XM_L2            &kp XM_L1            &none                &none                &kp LEFT             &kp DOWN             &kp UP               &kp RIGHT            &none
//├────────────────────┼────────────────────┼────────────────────┼────────────────────┼────────────────────┼────────────────────┼────────────────────┼────────────────────┼────────────────────┼────────────────────┼────────────────────┼────────────────────┤
   &none                &none                &kp XM_L0            &kp XM_L0            &kp XM_L0            &none                &none                &kp DEL              &kp HOME             &kp END              &none                &none
//╰────────────────────┴────────────────────┴────────────────────┼────────────────────┼────────────────────┼────────────────────┼────────────────────┼────────────────────┼────────────────────┼────────────────────┴────────────────────┴────────────────────╯
                                                                  &none                &trans               &trans               &trans               &trans               &none
//                                                               ╰────────────────────┴────────────────────┴────────────────────┴────────────────────┴────────────────────┴────────────────────╯
>;
          };
          text {
               display-name = "TEXT";
               bindings = <
//╭────────────────────┬────────────────────┬────────────────────┬────────────────────┬────────────────────┬────────────────────┬────────────────────┬────────────────────┬────────────────────┬────────────────────┬────────────────────┬────────────────────╮
   &none                &none                &select_home         &select_word         &select_line         &trans               &trans               &kp TAB              &kp ENTER            &kp ESC              &none                &none
//├────────────────────┼────────────────────┼────────────────────┼────────────────────┼────────────────────┼────────────────────┼────────────────────┼────────────────────┼────────────────────┼────────────────────┼────────────────────┼────────────────────┤
   &none                &none                &hsk XM_L3 XM_R3     &hsk XM_L2 XM_R2     &hsk XM_L1 XM_R1     &trans               &trans               &mc_prev_word        &kp DOWN             &kp UP               &mc_next_word        &none
//├────────────────────┼────────────────────┼────────────────────┼────────────────────┼────────────────────┼────────────────────┼────────────────────┼────────────────────┼────────────────────┼────────────────────┼────────────────────┼────────────────────┤
   &none                &none                &hsk XM_L0 RGUI      &hsk XM_L0 RGUI      &hsk XM_L0 RGUI      &trans               &trans               &mc_del_word         &kp HOME             &kp END              &none               &none
//╰────────────────────┴────────────────────┴────────────────────┼────────────────────┼────────────────────┼────────────────────┼────────────────────┼────────────────────┼────────────────────┼────────────────────┴────────────────────┴────────────────────╯
                                                                  &trans               &key_repeat          &none                &none                &key_repeat          &none
//                                                               ╰────────────────────┴────────────────────┴────────────────────┴────────────────────┴────────────────────┴────────────────────╯
>;
          };
          functions {
               display-name = "FUN";
               bindings = <
//╭────────────────────┬────────────────────┬────────────────────┬────────────────────┬────────────────────┬────────────────────┬────────────────────┬────────────────────┬────────────────────┬────────────────────┬────────────────────┬────────────────────╮
   &none                &none                &bt BT_PRV           &bt BT_NXT           &bt BT_SEL 0         &none                &none                &kp F7               &kp F8               &kp F9               &none                &none
//├────────────────────┼────────────────────┼────────────────────┼────────────────────┼────────────────────┼────────────────────┼────────────────────┼────────────────────┼────────────────────┼────────────────────┼────────────────────┼────────────────────┤
   &none                &none                &hsk XM_R3 XM_L3     &hsk XM_R2 XM_L2     &hsk XM_R1 XM_L1     &none                &none                &kp F4               &kp F5               &kp F6               &none                &none
//├────────────────────┼────────────────────┼────────────────────┼────────────────────┼────────────────────┼────────────────────┼────────────────────┼────────────────────┼────────────────────┼────────────────────┼────────────────────┼────────────────────┤
   &none                &none                &hsk RGUI XM_L0      &hsk RGUI XM_L0      &hsk RGUI XM_L0      &none                &none                &kp F1               &kp F2               &kp F3               &none                &none
//╰────────────────────┴────────────────────┴────────────────────┼────────────────────┼────────────────────┼────────────────────┼────────────────────┼────────────────────┼────────────────────┼────────────────────┴────────────────────┴────────────────────╯
                                                                  &trans               &bootloader          &none                &none                &key_repeat          &none
//                                                               ╰────────────────────┴────────────────────┴────────────────────┴────────────────────┴────────────────────┴────────────────────╯
>;
          };

          smart {
               display-name = "SMART";
               bindings = <
//╭────────────────────┬────────────────────┬────────────────────┬────────────────────┬────────────────────┬────────────────────┬────────────────────┬────────────────────┬────────────────────┬────────────────────┬────────────────────┬────────────────────╮
   &none                &none                &none                &tc_smart_word       &tc_smart_line       &none                &none                &mc_vim_replace      &mc_o_esc            &mc_sft_o_esc        &none                &none
//├────────────────────┼────────────────────┼────────────────────┼────────────────────┼────────────────────┼────────────────────┼────────────────────┼────────────────────┼────────────────────┼────────────────────┼────────────────────┼────────────────────┤
   &none                &none                &tc_snake_case       &tc_constant_case    &tc_kebab_case       &none                &none                &kp LS(XA_LB0)       &kp V                &kp LC(XA_LB0)       &none                &none
//├────────────────────┼────────────────────┼────────────────────┼────────────────────┼────────────────────┼────────────────────┼────────────────────┼────────────────────┼────────────────────┼────────────────────┼────────────────────┼────────────────────┤
   &none                &none                &tc_slash_case       &tc_pascal_case      &tc_camel_case       &none                &none                &mc_dqt0p            &mc_dqtplusp         &mc_dqtplusy         &none                &none
//╰────────────────────┴────────────────────┴────────────────────┼────────────────────┼────────────────────┼────────────────────┼────────────────────┼────────────────────┼────────────────────┼────────────────────┴────────────────────┴────────────────────╯
                                                                  &trans               &key_repeat          &mc_spc_esc          &trans               &bootloader          &none
//                                                               ╰────────────────────┴────────────────────┴────────────────────┴────────────────────┴────────────────────┴────────────────────╯
>;
          };

        };
};
